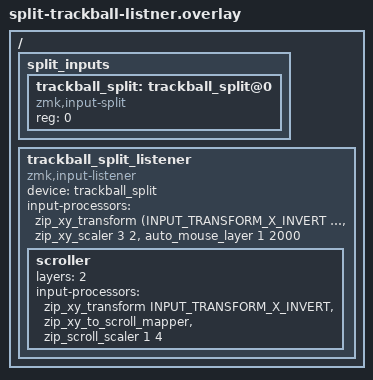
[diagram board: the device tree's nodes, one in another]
/{
    split_inputs {
        #address-cells = <1>;
        #size-cells = <0>;

        trackball_split: trackball_split@0 {
            compatible = "zmk,input-split";
            reg = <0>;
        };
    };

    trackball_split_listener: trackball_split_listener {
        compatible = "zmk,input-listener";
        device = <&trackball_split>;
        status = "okay";
        // Normal mode: Balanced speed (1.5x)
        input-processors = <
            &zip_xy_transform (INPUT_TRANSFORM_X_INVERT | INPUT_TRANSFORM_Y_INVERT)
            &zip_xy_scaler 3 2  // 1.5x speed
            &auto_mouse_layer 1 2000
        >;

        // Layer 2: Scroll mode
        scroller {
            layers = <2>;
            input-processors = <
                &zip_xy_transform INPUT_TRANSFORM_X_INVERT
                &zip_xy_to_scroll_mapper
                &zip_scroll_scaler 1 4  // 1/4x scroll speed
            >;
        };
     };
};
